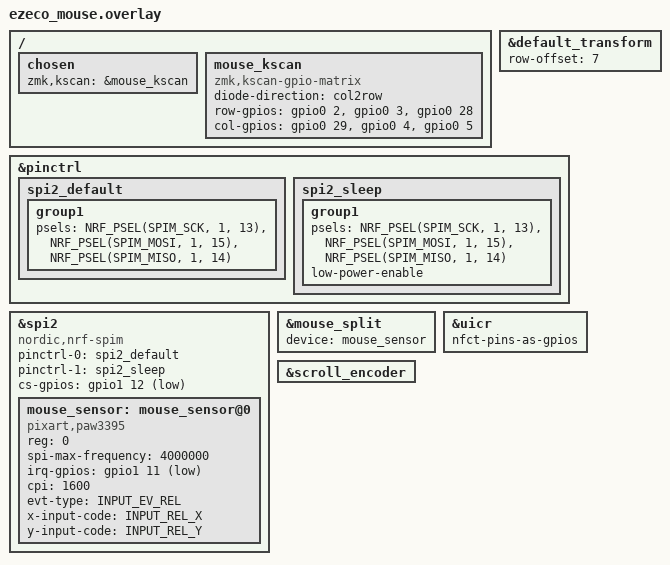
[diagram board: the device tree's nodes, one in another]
#include <zephyr/dt-bindings/input/input-event-codes.h>
#include "ezeco.dtsi"

/*
 * Mouse on Seeed XIAO nRF52840.
 *
 * Pin budget (11 edge pins + 2 NFC pads on the back):
 *   D8 P1.13 SCK, D9 P1.14 MISO, D10 P1.15 MOSI, D7 P1.12 CS, D6 P1.11 motion  -> PAW3395
 *   D0-D2 rows, D3-D5 cols                                                    -> 3x3 button matrix (8 used)
 *   NFC1 P0.09, NFC2 P0.10                                                    -> wheel encoder (ezeco.dtsi)
 * PROVISIONAL until the mouse electronics are bench tested (step M2).
 */

&default_transform {
    row-offset = <7>;
};

&pinctrl {
    spi2_default: spi2_default {
        group1 {
            psels = <NRF_PSEL(SPIM_SCK, 1, 13)>,
                    <NRF_PSEL(SPIM_MOSI, 1, 15)>,
                    <NRF_PSEL(SPIM_MISO, 1, 14)>;
        };
    };

    spi2_sleep: spi2_sleep {
        group1 {
            psels = <NRF_PSEL(SPIM_SCK, 1, 13)>,
                    <NRF_PSEL(SPIM_MOSI, 1, 15)>,
                    <NRF_PSEL(SPIM_MISO, 1, 14)>;
            low-power-enable;
        };
    };
};

&spi2 {
    compatible = "nordic,nrf-spim";
    status = "okay";
    pinctrl-0 = <&spi2_default>;
    pinctrl-1 = <&spi2_sleep>;
    pinctrl-names = "default", "sleep";
    cs-gpios = <&gpio1 12 GPIO_ACTIVE_LOW>;

    mouse_sensor: mouse_sensor@0 {
        compatible = "pixart,paw3395";
        status = "okay";
        reg = <0>;
        spi-max-frequency = <4000000>;
        irq-gpios = <&gpio1 11 (GPIO_ACTIVE_LOW | GPIO_PULL_UP)>;
        cpi = <1600>;
        evt-type = <INPUT_EV_REL>;
        x-input-code = <INPUT_REL_X>;
        y-input-code = <INPUT_REL_Y>;
    };
};

&mouse_split {
    status = "okay";
    device = <&mouse_sensor>;
};

// NFC pads P0.09/P0.10 used as GPIO for the wheel encoder.
&uicr {
    nfct-pins-as-gpios;
};

&scroll_encoder {
    status = "okay";
};

/ {
    chosen {
        zmk,kscan = &mouse_kscan;
    };

    mouse_kscan: mouse_kscan {
        compatible = "zmk,kscan-gpio-matrix";
        diode-direction = "col2row";
        row-gpios
            = <&gpio0 2 (GPIO_ACTIVE_HIGH | GPIO_PULL_DOWN)>
            , <&gpio0 3 (GPIO_ACTIVE_HIGH | GPIO_PULL_DOWN)>
            , <&gpio0 28 (GPIO_ACTIVE_HIGH | GPIO_PULL_DOWN)>
            ;
        col-gpios
            = <&gpio0 29 GPIO_ACTIVE_HIGH>
            , <&gpio0 4 GPIO_ACTIVE_HIGH>
            , <&gpio0 5 GPIO_ACTIVE_HIGH>
            ;
    };
};
